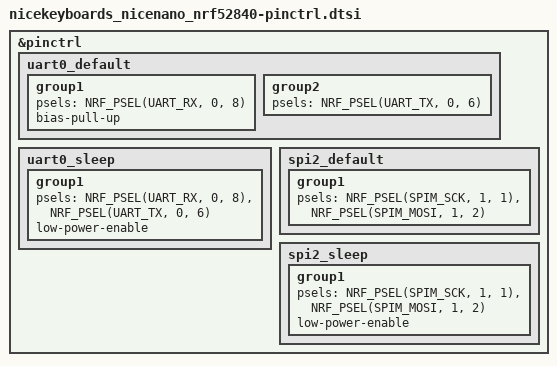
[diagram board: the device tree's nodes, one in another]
/*
* Copyright (c) 2023 Robert Wessels <robertinant@yahoo.com>
* SPDX-License-Identifier: Apache-2.0
*/

&pinctrl {
	uart0_default: uart0_default {
		group1 {
			psels = <NRF_PSEL(UART_RX, 0, 8)>;
			bias-pull-up;
		};
		group2 {
			psels = <NRF_PSEL(UART_TX, 0, 6)>;
		};
	};
	
	uart0_sleep: uart0_sleep {
		group1 {
			psels = <NRF_PSEL(UART_RX, 0, 8)>,
			<NRF_PSEL(UART_TX, 0, 6)>;
			low-power-enable;
		};
	};
	
	spi2_default: spi2_default {
		group1 {
			psels = <NRF_PSEL(SPIM_SCK, 1, 1)>,
			<NRF_PSEL(SPIM_MOSI, 1, 2)>;
		};
	};
	
	spi2_sleep: spi2_sleep {
		group1 {
			psels = <NRF_PSEL(SPIM_SCK, 1, 1)>,
			<NRF_PSEL(SPIM_MOSI, 1, 2)>;
			low-power-enable;
		};
	};
};
